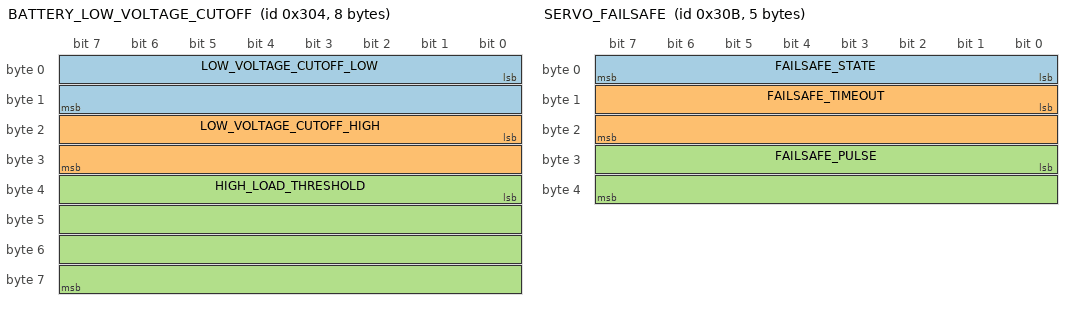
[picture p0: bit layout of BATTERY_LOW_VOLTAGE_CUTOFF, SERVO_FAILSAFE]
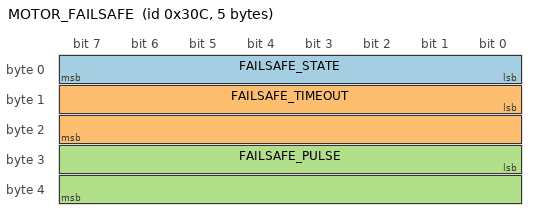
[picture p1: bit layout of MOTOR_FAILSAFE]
VERSION ""

NS_ :

BS_:

BU_:

BO_ 0x100 STEERING: 5 Vector__XXX
 SG_ STEERING_MODE M : 0|8@1+ (1,0) [0|0] "" Vector__XXX
 SG_ STEERING_PULSE_WIDTH m0 : 8|16@1+ (1,0) [0|0] "탎" Vector__XXX
 SG_ STEERING_ANGLE m1 : 8|32@1- (1,0) [-90|90] "degrees" Vector__XXX

BO_ 0x101 THROTTLE: 5 Vector__XXX
 SG_ THROTTLE_MODE M : 0|8@1+ (1,0) [0|0] "" Vector__XXX
 SG_ THROTTLE_PULSE_WIDTH m0 : 8|16@1+ (1,0) [0|0] "탎" Vector__XXX

BO_ 0x102 BRAKE_POWER: 1 Vector__XXX
 SG_ POWER : 0|8@1- (1,0) [0|0] "%" Vector__XXX

BO_ 0x200 BATTERY_CELL_VOLTAGES: 7 Vector__XXX
 SG_ CELLS M : 0|8@1+ (1,0) [0|0] "" Vector__XXX
 SG_ CELL_1_VOLTAGE m0 : 8|16@1+ (1,0) [0|0] "mV" Vector__XXX
 SG_ CELL_2_VOLTAGE m0 : 24|16@1+ (1,0) [0|0] "mV" Vector__XXX
 SG_ CELL_3_VOLTAGE m0 : 40|16@1+ (1,0) [0|0] "mV" Vector__XXX
 SG_ CELL_4_VOLTAGE m1 : 8|16@1+ (1,0) [0|0] "mV" Vector__XXX
 SG_ CELL_5_VOLTAGE m1 : 24|16@1+ (1,0) [0|0] "mV" Vector__XXX
 SG_ CELL_6_VOLTAGE m1 : 40|16@1+ (1,0) [0|0] "mV" Vector__XXX

BO_ 0x201 REGULATED_OUTPUT: 8 Vector__XXX
 SG_ REGULATED_OUTPUT_VOLTAGE : 0|32@1+ (1,0) [0|0] "mV" Vector__XXX
 SG_ REGULATED_OUTPUT_CURRENT : 32|32@1+ (1,0) [0|0] "mA" Vector__XXX

BO_ 0x202 BATTERY_OUTPUT: 8 Vector__XXX
 SG_ BATTERY_OUTPUT_VOLTAGE : 0|32@1+ (1,0) [0|0] "mV" Vector__XXX
 SG_ BATTERY_OUTPUT_CURRENT : 32|32@1+ (1,0) [0|0] "mA" Vector__XXX

BO_ 0x203 SERVO_VOLTAGE: 2 Vector__XXX
 SG_ SERVO_VOLTAGE : 0|16@1+ (1,0) [0|0] "mV" Vector__XXX

BO_ 0x204 SERVO_CURRENT: 2 Vector__XXX
 SG_ SERVO_CURRENT : 0|16@1+ (1,0) [0|0] "mA" Vector__XXX

BO_ 0x205 BATTERY_VOLTAGE: 2 Vector__XXX
 SG_ BATTERY_VOLTAGE : 0|16@1+ (1,0) [0|0] "mV" Vector__XXX

BO_ 0x206 SERVO_POSITION: 2 Vector__XXX
 SG_ SERVO_POSITION : 0|16@1- (1,0) [-90|90] "degrees" Vector__XXX

BO_ 0x207 WFL_H_BRIDGE_CURRENT: 2 Vector__XXX
 SG_ H_BRIDGE_CURRENT: 0|16@1+ (1,0) [0|0] "mA" Vector__XXX

BO_ 0x208 WFR_H_BRIDGE_CURRENT: 2 Vector__XXX
 SG_ H_BRIDGE_CURRENT: 0|16@1+ (1,0) [0|0] "mA" Vector__XXX

BO_ 0x209 WRL_H_BRIDGE_CURRENT: 2 Vector__XXX
 SG_ H_BRIDGE_CURRENT: 0|16@1+ (1,0) [0|0] "mA" Vector__XXX

BO_ 0x20A WRR_H_BRIDGE_CURRENT: 2 Vector__XXX
 SG_ H_BRIDGE_CURRENT: 0|16@1+ (1,0) [0|0] "mA" Vector__XXX

BO_ 0x210 WHEEL_FRONT_LEFT_SPEED: 8 Vector__XXX
 SG_ RPM : 0|32@1- (1,0) [0|0] "" Vector__XXX
 SG_ SPEED : 32|32@1- (1,0) [0|0] "km/h" Vector__XXX

BO_ 0x211 WHEEL_FRONT_RIGHT_SPEED: 8 Vector__XXX
 SG_ RPM : 0|32@1- (1,0) [0|0] "" Vector__XXX
 SG_ SPEED : 32|32@1- (1,0) [0|0] "km/h" Vector__XXX

BO_ 0x212 WHEEL_REAR_LEFT_SPEED: 8 Vector__XXX
 SG_ RPM : 0|32@1- (1,0) [0|0] "" Vector__XXX
 SG_ SPEED : 32|32@1- (1,0) [0|0] "km/h" Vector__XXX

BO_ 0x213 WHEEL_REAR_RIGHT_SPEED: 8 Vector__XXX
 SG_ RPM : 0|32@1- (1,0) [0|0] "" Vector__XXX
 SG_ SPEED : 32|32@1- (1,0) [0|0] "km/h" Vector__XXX

BO_ 0x300 BATTERY_JUMPER_CONFIG: 1 Vector__XXX
 SG_ JUMPER_CONFIG : 0|8@1+ (1,0) [0|0] "" BATTERY_MONITOR

BO_ 0x301 BATTERY_REGULATED_OUTPUT_VOLTAGE: 4 Vector__XXX
 SG_ REGULATED_OUTPUT_VOLTAGE : 0|32@1+ (1,0) [0|0] "mV" Vector__XXX

BO_ 0x302 BATTERY_OUTPUT_ON_OFF: 2 Vector__XXX
 SG_ MAIN_POWER_OUTPUT_STATE : 0|8@1+ (1,0) [0|0] "" Vector__XXX
 SG_ REGULATED_OUTPUT_STATE : 8|8@1+ (1,0) [0|0] "" Vector__XXX

BO_ 0x303 BATTERY_REPORT_FREQUENCY: 2 Vector__XXX
 SG_ REPORT_PERIOD : 0|16@1+ (1,0) [0|0] "ms" Vector__XXX

BO_ 0x304 BATTERY_LOW_VOLTAGE_CUTOFF: 8 Vector__XXX
 SG_ LOW_VOLTAGE_CUTOFF_LOW : 0|16@1+ (1,0) [0|0] "mV" Vector__XXX
 SG_ LOW_VOLTAGE_CUTOFF_HIGH : 16|16@1+ (1,0) [0|0] "mV" Vector__XXX
 SG_ HIGH_LOAD_THRESHOLD : 32|32@1+ (1,0) [0|0] "mA" Vector__XXX

BO_ 0x305 SERVO_SET_VOLTAGE: 2 Vector__XXX
 SG_ REQUESTED_SERVO_VOLTAGE : 0|16@1+ (1,0) [2740|10800] "mV" Vector__XXX

BO_ 0x306 SERVO_PWM_CONFIG: 2 Vector__XXX
 SG_ PWM_FREQUENCY : 0|16@1+ (1,0) [1|333] "Hz" Vector__XXX

BO_ 0x307 SERVO_REPORT_FREQUENCY: 2 Vector__XXX
 SG_ REPORT_PERIOD : 0|16@1+ (1,0) [0|0] "ms" Vector__XXX

BO_ 0x308 MOTOR_PWM_CONFIG: 2 Vector__XXX
 SG_ PWM_FREQUENCY : 0|16@1+ (1,0) [1|333] "Hz" Vector__XXX

BO_ 0x309 SERVO_REVERSE_DIRECTION: 0 Vector__XXX

BO_ 0x30A MOTOR_REVERSE_DIRECTION: 0 Vector__XXX

BO_ 0x30B SERVO_FAILSAFE: 5 Vector__XXX
 SG_ FAILSAFE_STATE : 0|8@1+ (1,0) [0|0] "" Vector__XXX
 SG_ FAILSAFE_TIMEOUT : 8|16@1+ (1,0) [0|0] "ms" Vector__XXX
 SG_ FAILSAFE_PULSE : 24|16@1+ (1,0) [0|0] "탎" Vector__XXX

BO_ 0x30C MOTOR_FAILSAFE: 5 Vector__XXX
 SG_ FAILSAFE_STATE : 0|8@1+ (1,0) [0|0] "" Vector__XXX
 SG_ FAILSAFE_TIMEOUT : 8|16@1+ (1,0) [0|0] "ms" Vector__XXX
 SG_ FAILSAFE_PULSE : 24|16@1+ (1,0) [0|0] "탎" Vector__XXX

BO_ 0x30D STEERING_SUBTRIM: 2 Vector__XXX
 SG_ SUBTRIM : 0|16@1- (1,0) [-500|500] "탎" Vector__XXX

BO_ 0x30E THROTTLE_SUBTRIM: 2 Vector__XXX
 SG_ SUBTRIM : 0|16@1- (1,0) [-500|500] "탎" Vector__XXX

BO_ 0x30F BATTERY_VBAT_OUT_OVERCURRENT_THRESHOLD: 4 Vector__XXX
 SG_ OVERCURRENT_THRESHOLD : 0|32@1+ (1,0) [0|0] "mA" Vector__XXX

BO_ 0x310 BATTERY_REG_OUT_OVERCURRENT_THRESHOLD: 4 Vector__XXX
 SG_ OVERCURRENT_THRESHOLD : 0|32@1+ (1,0) [0|0] "mA" Vector__XXX

BO_ 0x311 WHEEL_FRONT_LEFT_WHEEL_PARAMETERS: 8 Vector__XXX
 SG_ COG_COUNT : 0|32@1+ (1,0) [0|0] "" Vector__XXX
 SG_ WHEEL_DIAMETER : 32|32@1- (1,0) [0|0] "m" Vector__XXX

BO_ 0x312 WHEEL_FRONT_LEFT_REPORT_FREQUENCY: 2 Vector__XXX
 SG_ REPORT_PERIOD : 0|16@1+ (1,0) [0|0] "ms" Vector__XXX

BO_ 0x313 WHEEL_FRONT_RIGHT_WHEEL_PARAMETERS: 8 Vector__XXX
 SG_ COG_COUNT : 0|32@1+ (1,0) [0|0] "" Vector__XXX
 SG_ WHEEL_DIAMETER : 32|32@1- (1,0) [0|0] "m" Vector__XXX

BO_ 0x314 WHEEL_FRONT_RIGHT_REPORT_FREQUENCY: 2 Vector__XXX
 SG_ REPORT_PERIOD : 0|16@1+ (1,0) [0|0] "ms" Vector__XXX

BO_ 0x315 WHEEL_REAR_LEFT_WHEEL_PARAMETERS: 8 Vector__XXX
 SG_ COG_COUNT : 0|32@1+ (1,0) [0|0] "" Vector__XXX
 SG_ WHEEL_DIAMETER : 32|32@1- (1,0) [0|0] "m" Vector__XXX

BO_ 0x316 WHEEL_REAR_LEFT_REPORT_FREQUENCY: 2 Vector__XXX
 SG_ REPORT_PERIOD : 0|16@1+ (1,0) [0|0] "ms" Vector__XXX

BO_ 0x317 WHEEL_REAR_RIGHT_WHEEL_PARAMETERS: 8 Vector__XXX
 SG_ COG_COUNT : 0|32@1+ (1,0) [0|0] "" Vector__XXX
 SG_ WHEEL_DIAMETER : 32|32@1- (1,0) [0|0] "m" Vector__XXX

BO_ 0x318 WHEEL_REAR_RIGHT_REPORT_FREQUENCY: 2 Vector__XXX
 SG_ REPORT_PERIOD : 0|16@1+ (1,0) [0|0] "ms" Vector__XXX

BO_ 0x700 BOOTLOADER_COMMAND_ACK: 5 Vector__XXX
 SG_ ACK_TYPE : 0|8@1+ (1,0) [0|0] "" Vector__XXX
 SG_ COMMAND_ID : 8|32@1+ (1,0) [0|0] "" Vector__XXX

BO_ 0x701 BOOTLOADER_ENTER: 0 Vector__XXX

BO_ 0x702 BOOTLOADER_EXIT: 0 Vector__XXX

BO_ 0x703 BOOTLOADER_FLASH_ERASE: 4 Vector__XXX
 SG_ BYTES : 0|32@1+ (1,0) [0|0] "bytes" Vector__XXX

BO_ 0x704 BOOTLOADER_FORMAT_FS: 0 Vector__XXX

BO_ 0x705 BOOTLOADER_FLASH_PROGRAM: 8 Vector__XXX
 SG_ BLOCK_TRANSFER_PAGE M : 0|8@1+ (1,0) [0|0] "" Vector__XXX
 SG_ BLOCK_LENGTH m1 : 8|32@1+ (1,0) [0|0] "Bytes" Vector__XXX
 SG_ BUNDLE_PAGE_COUNT m2 : 8|16@1+ (1,0) [0|0] "" Vector__XXX
 SG_ DATA_A m3 : 8|56@1+ (1,0) [0|0] "" Vector__XXX
 SG_ DATA_B m4 : 8|56@1+ (1,0) [0|0] "" Vector__XXX

BO_ 0x706 BOOTLOADER_FLASH_CONFIG: 8 Vector__XXX
 SG_ BLOCK_TRANSFER_PAGE M : 0|8@1+ (1,0) [0|0] "" Vector__XXX
 SG_ BLOCK_LENGTH m1 : 8|32@1+ (1,0) [0|0] "Bytes" Vector__XXX
 SG_ BUNDLE_PAGE_COUNT m2 : 8|16@1+ (1,0) [0|0] "" Vector__XXX
 SG_ DATA_A m3 : 8|56@1+ (1,0) [0|0] "" Vector__XXX
 SG_ DATA_B m4 : 8|56@1+ (1,0) [0|0] "" Vector__XXX

VAL_ 0x100 STEERING_MODE 0 "PULSE_WIDTH_MODE" 1 "ANGLE_MODE" ;
VAL_ 0x101 THROTTLE_MODE 0 "PULSE_WIDTH_MODE" ;
VAL_ 0x200 CELLS 0 "CELLS_1_TO_3" 1 "CELLS_4_TO_6" ;
VAL_ 0x300 JUMPER_CONFIG 0 "X11_OFF_X12_OFF" 1 "X11_ON_X12_OFF" 2 "X11_OFF_X12_ON" 3 "X11_ON_X12_ON" ;
VAL_ 0x300 FUSE_CONFIG 0 "FUSE_50_AMPERE" 1 "FUSE_100_AMPERE"
VAL_ 0x302 REGULATED_OUTPUT_STATE 0 "OFF" 1 "ON" ;
VAL_ 0x302 MAIN_POWER_OUTPUT_STATE 0 "OFF" 1 "ON" ;
VAL_ 0x30B FAILSAFE_STATE 0 "OFF" 1 "ON" ;
VAL_ 0x30C FAILSAFE_STATE 0 "OFF" 1 "ON" ;
VAL_ 0x700 ACK_TYPE 0 "ACK" 1 "NACK" ;
VAL_ 0x705 BLOCK_TRANSFER_PAGE 0 "REQUEST_PAGE" 1 "SETUP_PAGE" 2 "BUNDLE_REQUEST_PAGE" 3 "DATA_PAGE" 4 "DATA_PAGE" 5 "ABORT_PAGE" ;
VAL_ 0x706 BLOCK_TRANSFER_PAGE 0 "REQUEST_PAGE" 1 "SETUP_PAGE" 2 "BUNDLE_REQUEST_PAGE" 3 "DATA_PAGE" 4 "DATA_PAGE" 5 "ABORT_PAGE" ;

SIG_VALTYPE_ 0x100 STEERING_ANGLE : 1
SIG_VALTYPE_ 0x210 RPM : 1;
SIG_VALTYPE_ 0x210 SPEED : 1;
SIG_VALTYPE_ 0x211 RPM : 1;
SIG_VALTYPE_ 0x211 SPEED : 1;
SIG_VALTYPE_ 0x212 RPM : 1;
SIG_VALTYPE_ 0x212 SPEED : 1;
SIG_VALTYPE_ 0x213 RPM : 1;
SIG_VALTYPE_ 0x213 SPEED : 1;
SIG_VALTYPE_ 0x311 WHEEL_DIAMETER : 1;
SIG_VALTYPE_ 0x313 WHEEL_DIAMETER : 1;
SIG_VALTYPE_ 0x315 WHEEL_DIAMETER : 1;
SIG_VALTYPE_ 0x317 WHEEL_DIAMETER : 1;
